# V8M_Generic register map
Vendor: ARM Ltd.; Series: M; File version: 2020-08-22T15:13:24.354567-05:00
CPU: CM4 r0p0, little endian, vendor SysTick, 8 interrupt priority bits
Registers are 32-bit, read-write, no defined reset value unless marked. A register's access mark holds for its fields unless they carry their own. Offsets are from the block's base; [hi:lo] are bit positions; {n}, {i} and the like mark numbered series; 'fields as' and 'values as' point back to an identical list.

## MPU — Memory protection Unit Control Registers
Base 0xE000ED90
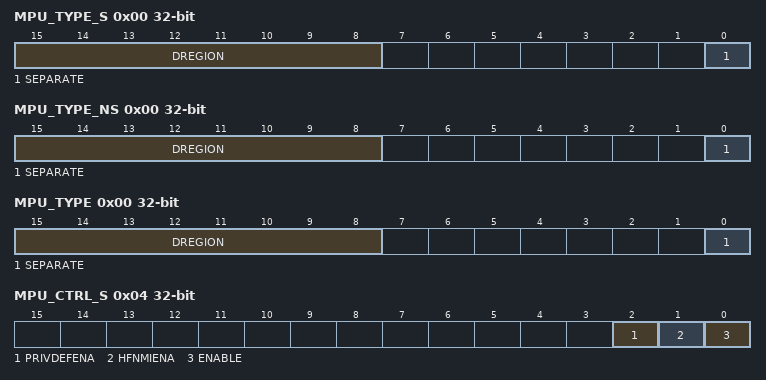
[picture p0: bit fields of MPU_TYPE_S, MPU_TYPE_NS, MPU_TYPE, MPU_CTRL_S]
0x00 MPU_TYPE_S ro — The MPU Type Register indicates how many regions the MPU FTSSS supports
  [15:8] DREGION — Data regions
  [0] SEPARATE
0x00 MPU_TYPE_NS ro — The MPU Type Register indicates how many regions the MPU FTSSS supports
  [15:8] DREGION — Data regions
  [0] SEPARATE
0x00 MPU_TYPE ro — The MPU Type Register indicates how many regions the MPU FTSSS supports
  [15:8] DREGION — Data regions
  [0] SEPARATE
0x04 MPU_CTRL_S — Enables the MPU and, when the MPU is enabled, controls whether the default memory map is enabled as a background region for privileged accesses, and whether the MPU is enabled for HardFaults, NMIs, and exception handlers when FAULTMASK is set to 1
  [2] PRIVDEFENA — Privileged default enable
    0=Use_of_default_memory_map_disabled; 1=Use_of_default_memory_map_enabled_for_privilege_code
  [1] HFNMIENA — HardFault, NMI enable
    0=MPU_disabled_for_these_handlers; 1=MPU_enabled_for_these_handlers
  [0] ENABLE
    0=The_MPU_is_disabled; 1=The_MPU_is_enabled
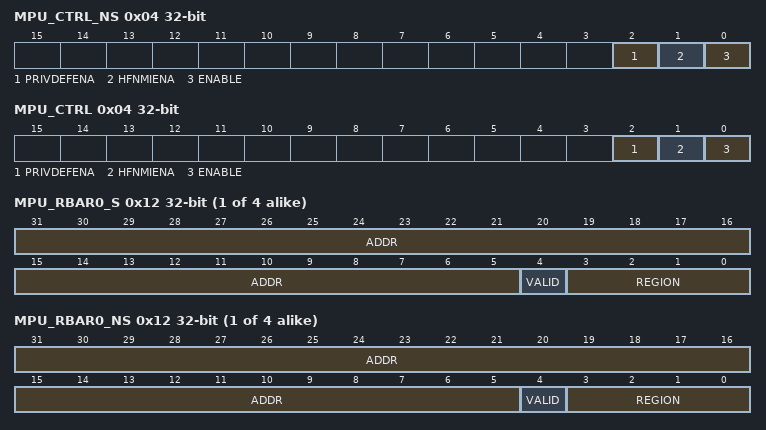
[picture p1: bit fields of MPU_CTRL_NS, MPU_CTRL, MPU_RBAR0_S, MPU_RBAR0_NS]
0x04 MPU_CTRL_NS — Enables the MPU and, when the MPU is enabled, controls whether the default memory map is enabled as a background region for privileged accesses, and whether the MPU is enabled for HardFaults, NMIs, and exception handlers when FAULTMASK is set to 1
  fields as MPU_CTRL_S
0x04 MPU_CTRL — Enables the MPU and, when the MPU is enabled, controls whether the default memory map is enabled as a background region for privileged accesses, and whether the MPU is enabled for HardFaults, NMIs, and exception handlers when FAULTMASK is set to 1
  fields as MPU_CTRL_S
0x08 MPU_RNR_S — Selects the region currently accessed by MPU_RBAR and MPU_RLAR
  [7:0] REGION — Region number
0x08 MPU_RNR_NS — Selects the region currently accessed by MPU_RBAR and MPU_RLAR
  [7:0] REGION — Region number
0x08 MPU_RNR — Selects the region currently accessed by MPU_RBAR and MPU_RLAR
  [7:0] REGION — Region number
0x12 MPU_RBAR{i}_S (i=0..3) — Provides indirect read and write access to the base address of the currently selected MPU region FTSSS
  [31:5] ADDR, [4] VALID, [3:0] REGION
0x12 MPU_RBAR{i}_NS (i=0..3) — Provides indirect read and write access to the base address of the currently selected MPU region FTSSS
  [31:5] ADDR, [4] VALID, [3:0] REGION
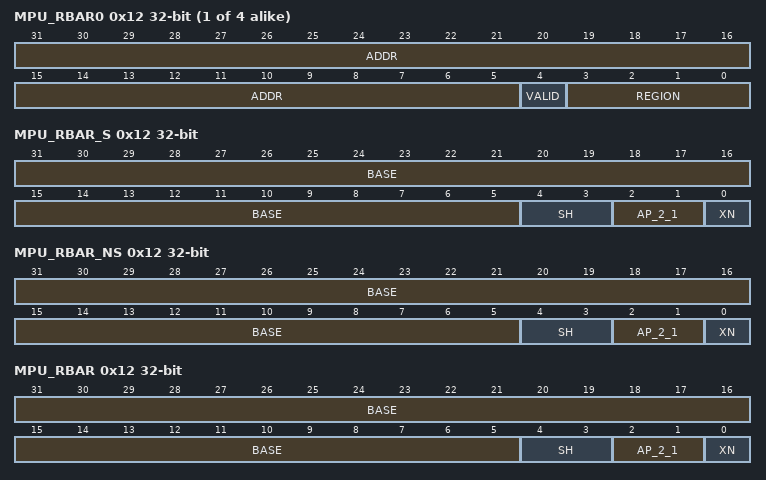
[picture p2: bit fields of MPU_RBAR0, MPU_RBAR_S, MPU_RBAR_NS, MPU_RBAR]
0x12 MPU_RBAR{i} (i=0..3) — Provides indirect read and write access to the base address of the currently selected MPU region FTSSS
  [31:5] ADDR, [4] VALID, [3:0] REGION
0x12 MPU_RBAR_S — Provides indirect read and write access to the base address of the currently selected MPU region FTSSS
  [31:5] BASE — Base address
  [4:3] SH — Shareability
    0=Non_shareable; 2=Outer_Shareable; 3=Inner_Shareable
  [2:1] AP_2_1 — Access permissions
    0=Read_write_by_privileged_code_only; 1=Read_write_by_any_privilege_level; 2=Read_only_by_privileged_code_only; 3=Read_only_by_any_privilege_level
  [0] XN — Execute Never
    0=Execution_only_permitted_if_read_permitted; 1=Execution_not_permitted
0x12 MPU_RBAR_NS — Provides indirect read and write access to the base address of the currently selected MPU region FTSSS
  fields as MPU_RBAR_S
0x12 MPU_RBAR — Provides indirect read and write access to the base address of the currently selected MPU region FTSSS
  fields as MPU_RBAR_S
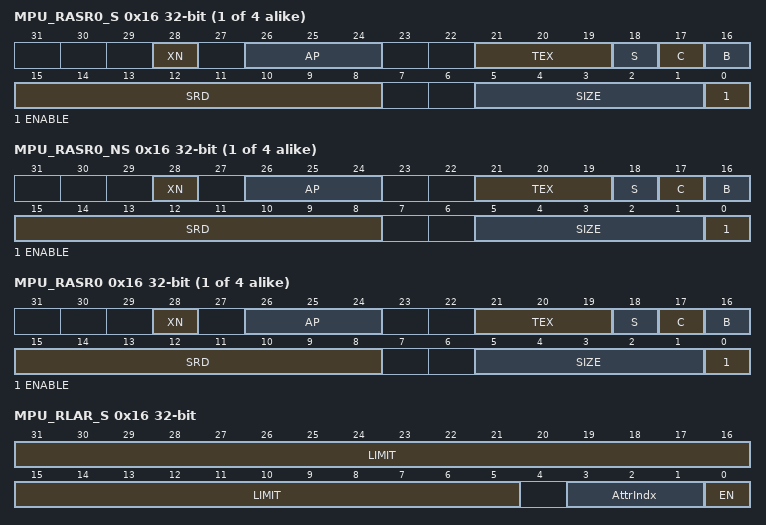
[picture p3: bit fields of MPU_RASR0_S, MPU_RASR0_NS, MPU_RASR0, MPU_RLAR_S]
0x16 MPU_RASR{i}_S (i=0..3) — Provides indirect read and write access to the limit address of the currently selected MPU region FTSSS
  [28] XN, [26:24] AP, [21:19] TEX, [18] S, [17] C, [16] B, [15:8] SRD, [5:1] SIZE, [0] ENABLE
0x16 MPU_RASR{i}_NS (i=0..3) — Provides indirect read and write access to the limit address of the currently selected MPU region FTSSS
  fields as MPU_RASR0_S
0x16 MPU_RASR{i} (i=0..3) — Provides indirect read and write access to the limit address of the currently selected MPU region FTSSS
  fields as MPU_RASR0_S
0x16 MPU_RLAR_S — Provides indirect read and write access to the limit address of the currently selected MPU region FTSSS
  [31:5] LIMIT — Limit address
  [3:1] AttrIndx — Attribute index
  [0] EN — Enable
    0=Region_disabled; 1=Region_enabled
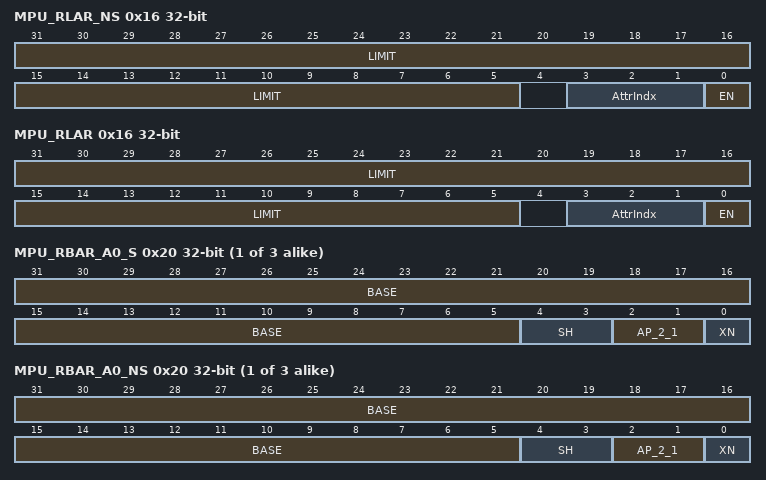
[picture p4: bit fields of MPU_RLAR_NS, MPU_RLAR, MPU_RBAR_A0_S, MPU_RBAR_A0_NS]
0x16 MPU_RLAR_NS — Provides indirect read and write access to the limit address of the currently selected MPU region FTSSS
  fields as MPU_RLAR_S
0x16 MPU_RLAR — Provides indirect read and write access to the limit address of the currently selected MPU region FTSSS
  fields as MPU_RLAR_S
0x20 MPU_RBAR_A{i}_S (i=0..2) — Provides indirect read and write access to the base address of the MPU region selected by MPU_RNR[7:2]:({i}[1:0]) FTSSS
  fields as MPU_RBAR_S
0x20 MPU_RBAR_A{i}_NS (i=0..2) — Provides indirect read and write access to the base address of the MPU region selected by MPU_RNR[7:2]:({i}[1:0]) FTSSS
  fields as MPU_RBAR_S
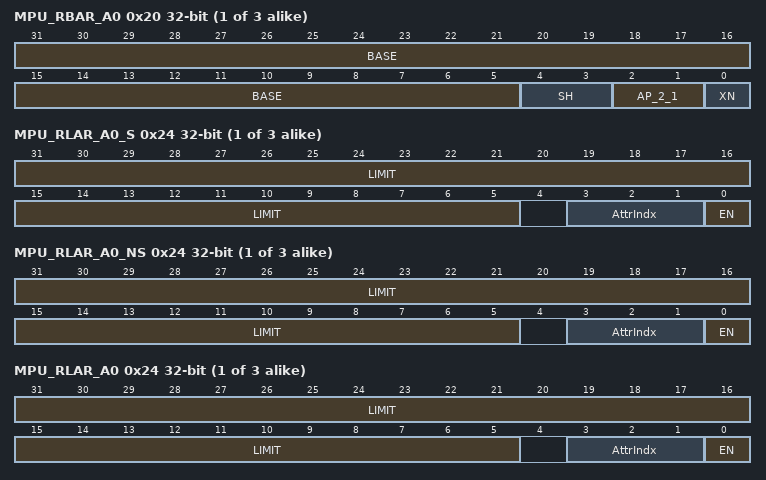
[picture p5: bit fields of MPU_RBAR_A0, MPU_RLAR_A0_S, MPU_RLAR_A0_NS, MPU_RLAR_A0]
0x20 MPU_RBAR_A{i} (i=0..2) — Provides indirect read and write access to the base address of the MPU region selected by MPU_RNR[7:2]:({i}[1:0]) FTSSS
  fields as MPU_RBAR_S
0x24 MPU_RLAR_A{i}_S (i=0..2) — Provides indirect read and write access to the limit address of the currently selected MPU region selected by MPU_RNR[7:2]:({i}[1:0]) FTSSS
  fields as MPU_RLAR_S
0x24 MPU_RLAR_A{i}_NS (i=0..2) — Provides indirect read and write access to the limit address of the currently selected MPU region selected by MPU_RNR[7:2]:({i}[1:0]) FTSSS
  fields as MPU_RLAR_S
0x24 MPU_RLAR_A{i} (i=0..2) — Provides indirect read and write access to the limit address of the currently selected MPU region selected by MPU_RNR[7:2]:({i}[1:0]) FTSSS
  fields as MPU_RLAR_S
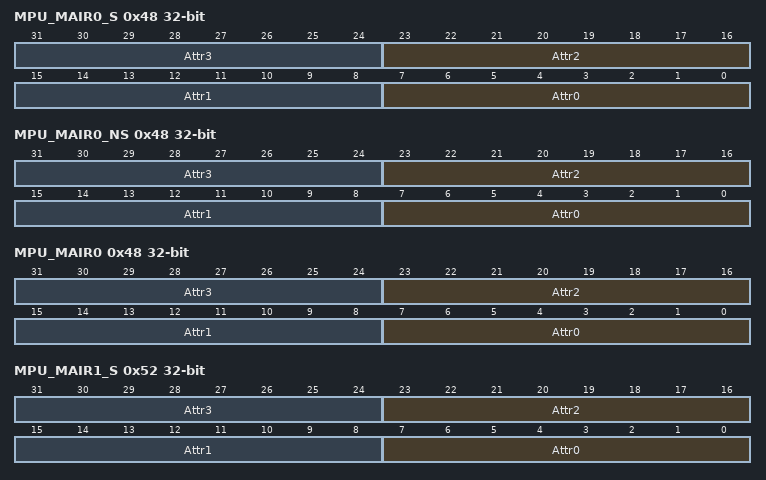
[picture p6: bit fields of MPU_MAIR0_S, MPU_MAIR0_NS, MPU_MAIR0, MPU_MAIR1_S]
0x48 MPU_MAIR0_S — Along with MPU_MAIR1, provides the memory attribute encodings corresponding to the AttrIndx values
  [all] fields
    0=See_MAIR_ATTR_for_encoding
  [8n+7:8n] Attr{n} (n=0..3) — Attribute {n}
0x48 MPU_MAIR0_NS — Along with MPU_MAIR1, provides the memory attribute encodings corresponding to the AttrIndx values
  fields as MPU_MAIR0_S
0x48 MPU_MAIR0 — Along with MPU_MAIR1, provides the memory attribute encodings corresponding to the AttrIndx values
  fields as MPU_MAIR0_S
0x52 MPU_MAIR1_S — Along with MPU_MAIR0, provides the memory attribute encodings corresponding to the AttrIndx values
  fields as MPU_MAIR0_S
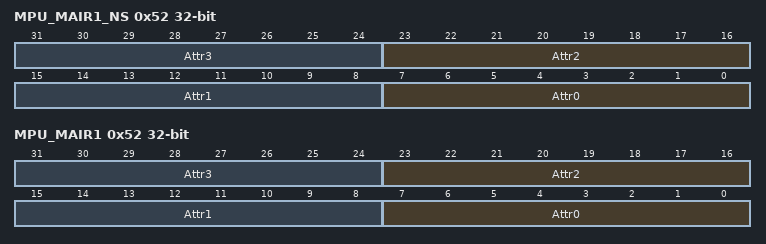
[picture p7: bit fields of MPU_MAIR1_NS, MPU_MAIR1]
0x52 MPU_MAIR1_NS — Along with MPU_MAIR0, provides the memory attribute encodings corresponding to the AttrIndx values
  fields as MPU_MAIR0_S
0x52 MPU_MAIR1 — Along with MPU_MAIR0, provides the memory attribute encodings corresponding to the AttrIndx values
  fields as MPU_MAIR0_S
